# bcm2837_lpa register map
Vendor: BROADCOM; Series: BCM2837; File version: A
CPU: CA72 r0p0, little endian, MPU, FPU, 2 interrupt priority bits
Registers are 32-bit, read-write, reset 0x0 unless marked. A register's access mark holds for its fields unless they carry their own. Offsets are from the block's base; [hi:lo] are bit positions; {n}, {i} and the like mark numbered series.

## AUX — Three auxiliary peripherals
Base 0x3F215000
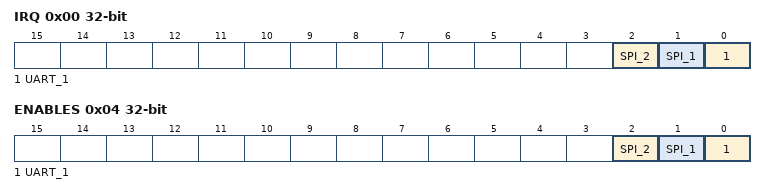
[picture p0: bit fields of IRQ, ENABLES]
0x00 IRQ — Interrupt status
  [2] SPI_2 — SPI2 interrupt active
  [1] SPI_1 — SPI1 interrupt active
  [0] UART_1 — UART1 interrupt active
0x04 ENABLES — Enable sub-peripherals
  [2] SPI_2 — SPI2 enabled
  [1] SPI_1 — SPI1 enabled
  [0] UART_1 — UART1 enabled

## UART1 — Mini UART
Base 0x3F215040
0x00 IO — I/O Data
  [7:0] DATA — FIFO access
0x00 BAUDL 8-bit (alternate view of IO) — Lower bits of baudrate when DLAB is set
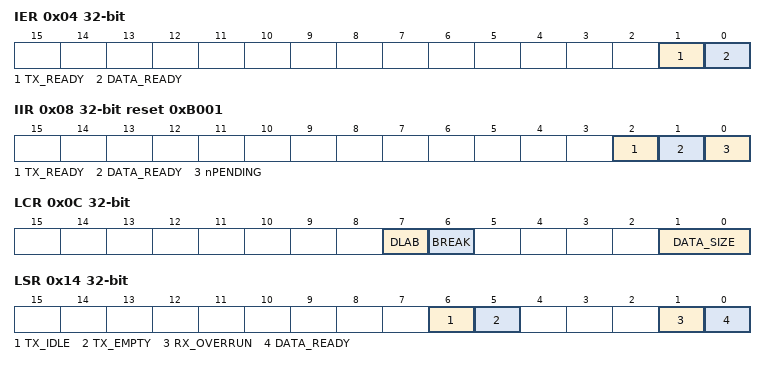
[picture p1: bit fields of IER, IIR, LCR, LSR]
0x04 IER — Interrupt Enable
  [1] TX_READY — Transmit FIFO is empty
  [0] DATA_READY — Receive FIFO has at least 1 byte
0x04 BAUDH 8-bit (alternate view of IER) — High bits of baudrate when DLAB is set
0x08 IIR reset 0xB001 — Interrupt Identify
  [2] TX_READY — Transmit FIFO is empty
  [1] DATA_READY — Receive FIFO has at least 1 byte
  [0] nPENDING — No pending interrupt
0x0C LCR — Line control
  [7] DLAB — First two registers are baudrate
  [6] BREAK — Pull TX low continuously to send break
  [1:0] DATA_SIZE — UART word size
    0=7BIT; 3=8BIT
0x10 MCR — Modem Control
  [1] RTS — RTS is low
0x14 LSR — Line Status
  [6] TX_IDLE — Transmit FIFO empty and all bits shifted out
  [5] TX_EMPTY — Transmit FIFO has room for at least one byte
  [1] RX_OVERRUN — Receive FIFO overrun
  [0] DATA_READY — Receive FIFO has at least one byte
0x18 MSR — Modem Status
  [4] CTS — CTS is low
0x1C SCRATCH 8-bit
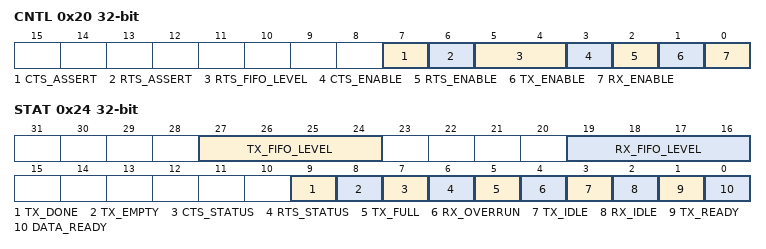
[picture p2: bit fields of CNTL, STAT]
0x20 CNTL — Control
  [7] CTS_ASSERT — CTS assert level
    0=HIGH (Assert high); 1=LOW (Assert low)
  [6] RTS_ASSERT — RTS assert level
    0=HIGH (Assert high); 1=LOW (Assert low)
  [5:4] RTS_FIFO_LEVEL — FIFO level to de-assert RTS
    0=3EMPTY (3 empty spaces); 1=2EMPTY (2 empty spaces); 2=1EMPTY (1 empty spaces); 3=4EMPTY (4 empty spaces)
  [3] CTS_ENABLE — Enable auto transmit flow control with CTS
  [2] RTS_ENABLE — Enable auto receive flow control with RTS
  [1] TX_ENABLE — Enable transmit
  [0] RX_ENABLE — Enable receive
0x24 STAT — Status
  [27:24] TX_FIFO_LEVEL — How many entries are filled in the TX FIFO
  [19:16] RX_FIFO_LEVEL — How many entries are filled in the RX FIFO
  [9] TX_DONE — Transmit FIFO is empty and transmitter is idle
  [8] TX_EMPTY — Transmit FIFO is completely empty
  [7] CTS_STATUS — CTS state
  [6] RTS_STATUS — RTS state
  [5] TX_FULL — Transmit FIFO is full
  [4] RX_OVERRUN — Receive FIFO overrun
  [3] TX_IDLE — Transmitter is idle
  [2] RX_IDLE — Receiver is idle
  [1] TX_READY — Transmit FIFO has space for at least one symbol
  [0] DATA_READY — Receive FIFO has at least one symbol
0x28 BAUD 16-bit — Baudrate

## SPI1 — Aux SPI
Base 0x3F215080
Same registers: SPI2 0x3F2150C0
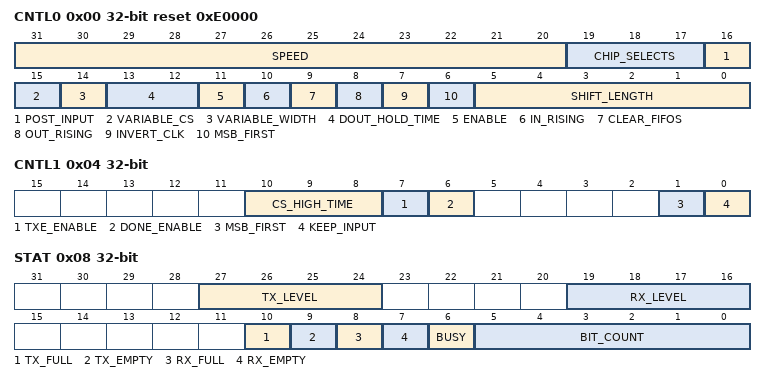
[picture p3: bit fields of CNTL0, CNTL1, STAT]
0x00 CNTL0 reset 0xE0000 — Control 0
  [31:20] SPEED — SPI clock speed. clk = sys / 2 * (SPEED + 1)
  [19:17] CHIP_SELECTS — The CS pattern when active
  [16] POST_INPUT — Post input mode
  [15] VARIABLE_CS — Take CS pattern and data from TX FIFO (along with VARIABLE_WIDTH)
  [14] VARIABLE_WIDTH — Take shift length and data from FIFO
  [13:12] DOUT_HOLD_TIME — Controls extra DOUT hold time in system clock cycles
    0=0; 1=1; 2=4; 3=7
  [11] ENABLE — Enable the interface
  [10] IN_RISING — Data is clocked in on rising edge of CLK
  [9] CLEAR_FIFOS
  [8] OUT_RISING — Data is clocked out on rising edge of CLK
  [7] INVERT_CLK — Idle clock high
  [6] MSB_FIRST — Shift out the most significant bit (MSB) first
  [5:0] SHIFT_LENGTH — Number of bits to shift
0x04 CNTL1 — Control 1
  [10:8] CS_HIGH_TIME — Additional SPI clock cycles where CS is high
  [7] TXE_ENABLE — Enable TX empty interrupt
  [6] DONE_ENABLE — Enable DONE interrupt
  [1] MSB_FIRST — Shift the most significant bit first (MSB)
  [0] KEEP_INPUT — Don't clear the RX shift register before a new transaction
0x08 STAT — Status
  [27:24] TX_LEVEL — Number of entries in TX FIFO
  [19:16] RX_LEVEL — Number of entries in RX FIFO
  [10] TX_FULL — TX FIFO is full
  [9] TX_EMPTY — TX FIFO is empty
  [8] RX_FULL — RX FIFO is full
  [7] RX_EMPTY — RX FIFO is empty
  [6] BUSY — Indicates a transfer is ongoing
  [5:0] BIT_COUNT — Number of bits left to be processed.
0x0C PEEK ro — Read the RXFIFO without removing an entry
  [15:0] DATA — FIFO data access
{0x20+4i} IO{i} (i=0..3) — Writing to the FIFO will deassert CS at the end of the access
  [15:0] DATA — FIFO data access
{0x30+4i} TXHOLD{i} (i=0..3) — Writing to the FIFO will maintain CS at the end of the access
  [15:0] DATA — FIFO data access
